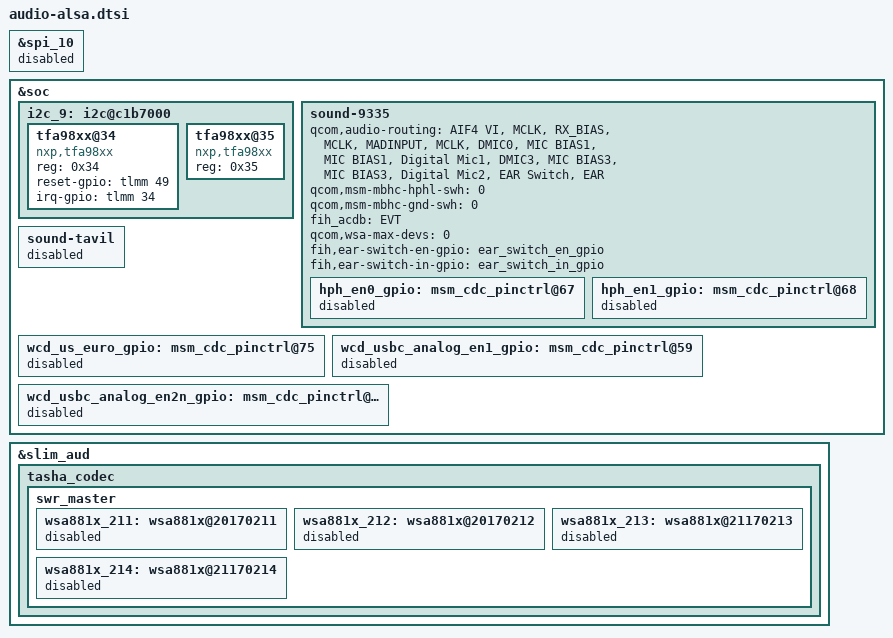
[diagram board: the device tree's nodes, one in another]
&spi_10 {
	status = "disabled";
};

&soc {
	i2c_9: i2c@c1b7000 { /* BLSP2 QUP3 */
		status = "okay";
		tfa98xx@34 { /* Bot */
			compatible = "nxp,tfa98xx";
			reg = <0x34>;
			reset-gpio = <&tlmm 49 0>;
			irq-gpio = <&tlmm 34 0>;
		};

		tfa98xx@35 { /* Top */
			compatible = "nxp,tfa98xx";
			reg = <0x35>;
		};
	};

	sound-9335 {
		qcom,audio-routing =
			"AIF4 VI", "MCLK",
			"RX_BIAS", "MCLK",
			"MADINPUT", "MCLK",
			"DMIC0", "MIC BIAS1",
			"MIC BIAS1", "Digital Mic1",
			"DMIC3", "MIC BIAS3",
			"MIC BIAS3", "Digital Mic2",
			"EAR Switch", "EAR";

		qcom,msm-mbhc-hphl-swh = <0>;
		qcom,msm-mbhc-gnd-swh = <0>;
		fih_acdb = "EVT";
		/delete-property/ qcom,us-euro-gpios;
		/delete-property/ qcom,hph-en0-gpio;
		/delete-property/ qcom,hph-en1-gpio;

		qcom,wsa-max-devs = <0>;

		/delete-property/ qcom,wsa-devs;
		/delete-property/ qcom,wsa-aux-dev-prefix;

		fih,ear-switch-en-gpio = <&ear_switch_en_gpio>;
		fih,ear-switch-in-gpio = <&ear_switch_in_gpio>;

		hph_en0_gpio: msm_cdc_pinctrl@67 {
			status = "disabled";
		};

		hph_en1_gpio: msm_cdc_pinctrl@68 {
			status = "disabled";
		};
	};

	sound-tavil {
		status = "disabled";
	};

	wcd_us_euro_gpio: msm_cdc_pinctrl@75 {
		status = "disabled";
	};

	wcd_usbc_analog_en1_gpio: msm_cdc_pinctrl@59 {
		status = "disabled";
	};

	wcd_usbc_analog_en2n_gpio: msm_cdc_pinctrl@60 {
		status = "disabled";
	};
};

&slim_aud {
	tasha_codec {
		swr_master {
			wsa881x_211: wsa881x@20170211 {
				status = "disabled";
			};

			wsa881x_212: wsa881x@20170212 {
				status = "disabled";
			};

			wsa881x_213: wsa881x@21170213 {
				status = "disabled";
			};

			wsa881x_214: wsa881x@21170214 {
				status = "disabled";
			};
		};
	};
};
